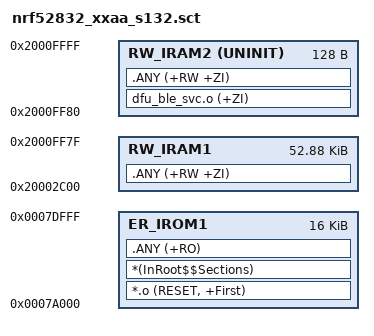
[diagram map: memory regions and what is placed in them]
; *************************************************************
; *** Scatter-Loading Description File generated by uVision ***
; *************************************************************

LR_IROM1 0x0007A000 0x00004000  {    ; load region size_region
  ER_IROM1 0x0007A000 0x00004000  {  ; load address = execution address
   *.o (RESET, +First)
   *(InRoot$$Sections)
   .ANY (+RO)
  }
  RW_IRAM1 0x20002C00 0x0000D380  {  ; RW data
   .ANY (+RW +ZI)
  }
  RW_IRAM2 0x2000FF80 UNINIT 0x00000080  {
    dfu_ble_svc.o (+ZI)
   .ANY (+RW +ZI)
  }
}

